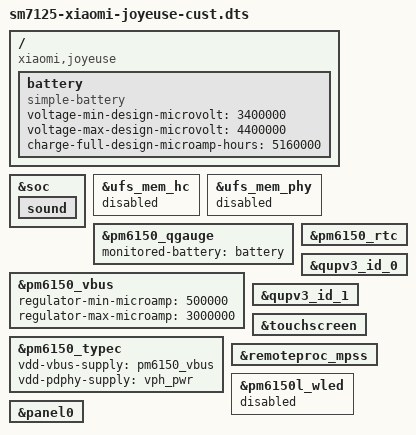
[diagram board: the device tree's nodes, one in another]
#include "sm7125-xiaomi-joyeuse.dts"
#include "sm7125-xiaomi-joyeuse-display.dts"
#include "sm7125-xiaomi-joyeuse-touch.dts"
#include "sm7125-xiaomi-joyeuse-camera.dts"

&soc {
        sound: sound { };
};

#include "sm7125-xiaomi-joyeuse-sound.dts"

/* must add sc7180 into compatible machine or add cpu blocklist with sm7125 */
/ {
	compatible = "xiaomi,joyeuse", "db845c", "qcom,sm7125", "qcom,sc7180";

	battery: battery {
		compatible = "simple-battery";

		voltage-min-design-microvolt = <3400000>;
		voltage-max-design-microvolt = <4400000>;

		charge-full-design-microamp-hours = <5160000>;
	};
};

/* that can protect ufs partition untouch */
&ufs_mem_hc {
	status = "disabled";
};

&ufs_mem_phy {
	status = "disabled";
};

&pm6150_qgauge {
	status = "okay";
};

&pm6150_rtc {
	status = "okay";
};

&pm6150_vbus {
	regulator-min-microamp = <500000>;
	regulator-max-microamp = <3000000>;
	status = "okay";
};

&pm6150_typec {
	vdd-vbus-supply = <&pm6150_vbus>;
	vdd-pdphy-supply = <&vph_pwr>;	
	status = "okay";
};

&qupv3_id_0 {
	status = "okay";
};

&qupv3_id_1 {
	status = "okay";
};

&pm6150_qgauge {
        monitored-battery = <&battery>;
        status = "okay";
};

&touchscreen {
//	status = "disabled";
};

&remoteproc_mpss {
	status = "okay";
};

&pm6150l_wled {
	status = "disabled";
};

&panel0 {
	/*
	 * since wled crashed and above disabled it,
	 * then panel backlight also need to disabled at once
	 */
	/delete-property/ backlight;
};
